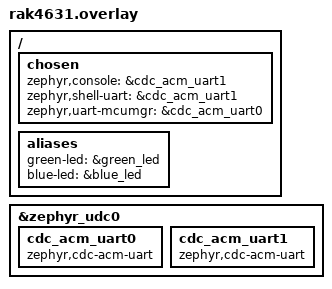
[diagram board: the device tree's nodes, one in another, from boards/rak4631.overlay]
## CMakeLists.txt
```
# Copyright (c) 2025 Kenneth Lu
#
# SPDX-License-Identifier: Apache-2.0

cmake_minimum_required(VERSION 3.20.0)

set(COMMON_PATH ${CMAKE_CURRENT_SOURCE_DIR}/../common)
include(${COMMON_PATH}/common.cmake)

find_package(Zephyr REQUIRED HINTS $ENV{ZEPHYR_BASE})
project(qthinger LANGUAGES C VERSION 1.0.0)

# determine git tag and commit hash for automatic firmware versioning
find_package(Git)
if(GIT_FOUND)
    execute_process(
        COMMAND ${GIT_EXECUTABLE} describe --long --dirty --tags
        OUTPUT_VARIABLE FIRMWARE_VERSION_ID
        OUTPUT_STRIP_TRAILING_WHITESPACE)
else()
    set(FIRMWARE_VERSION_ID "unknown")
endif()

add_definitions(-DFIRMWARE_VERSION_ID="${FIRMWARE_VERSION_ID}")

target_include_directories(app PRIVATE ${CMAKE_BINARY_DIR}/app/include src)
target_sources_ifdef(CONFIG_BOARD_RAK4631_NRF52840 app PRIVATE boards/board.c)
target_sources(app PRIVATE
      src/main.c
      src/data_objects.c
      src/ts_sensor.c
)
```

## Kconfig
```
# Copyright (c) 2021 Nordic Semiconductor ASA
#
# SPDX-License-Identifier: Apache-2.0

source "Kconfig.zephyr"

choice WISBLOCK_LORAWAN_REGION
	prompt "WisBlock LoRaWAN Region"
	default WISBLOCK_REGION_AS923
	help
	  Select the LoRaWAN region to use. This wrapper ensures only one
	  region is active at a time.

config WISBLOCK_REGION_AS923
	bool "Asia 923MHz (AS923)"
	select LORAMAC_REGION_AS923

config WISBLOCK_REGION_AU915
	bool "Australia 915MHz (AU915)"
	select LORAMAC_REGION_AU915

config WISBLOCK_REGION_CN470
	bool "China 470MHz (CN470)"
	select LORAMAC_REGION_CN470

config WISBLOCK_REGION_CN779
	bool "China 779MHz (CN779)"
	select LORAMAC_REGION_CN779

config WISBLOCK_REGION_EU433
	bool "Europe 433MHz (EU433)"
	select LORAMAC_REGION_EU433

config WISBLOCK_REGION_EU868
	bool "Europe 868MHz (EU868)"
	select LORAMAC_REGION_EU868

config WISBLOCK_REGION_KR920
	bool "Korea 920MHz (KR920)"
	select LORAMAC_REGION_KR920

config WISBLOCK_REGION_IN865
	bool "India 865MHz (IN865)"
	select LORAMAC_REGION_IN865

config WISBLOCK_REGION_US915
	bool "US 915MHz (US915)"
	select LORAMAC_REGION_US915

config WISBLOCK_REGION_RU864
	bool "Russia 864MHz (RU864)"
	select LORAMAC_REGION_RU864

endchoice
```

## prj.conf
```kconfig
CONFIG_LOG=y
CONFIG_MAIN_STACK_SIZE=2048
CONFIG_SYSTEM_WORKQUEUE_STACK_SIZE=2048

CONFIG_SHELL=y
CONFIG_NVS=y
CONFIG_ARM_MPU=n
CONFIG_FLASH=y
CONFIG_FLASH_PAGE_LAYOUT=y
CONFIG_FLASH_MAP=y
CONFIG_REBOOT=y

# ThingSet
CONFIG_THINGSET=y
CONFIG_THINGSET_SDK=y
CONFIG_THINGSET_NODE_NAME="RAKTS"
CONFIG_THINGSET_SHELL=y
CONFIG_THINGSET_SHELL_REPORTING=n
CONFIG_THINGSET_STORAGE=y
CONFIG_SHELL_WILDCARD=n
CONFIG_MPU_ALLOW_FLASH_WRITE=y
CONFIG_THINGSET_AUTH=y
CONFIG_THINGSET_AUTH_TOKEN_EXPERT="expert"
CONFIG_THINGSET_AUTH_TOKEN_MANUFACTURER="manufacturer"

CONFIG_BT=y
CONFIG_BT_PERIPHERAL=y
CONFIG_BT_DEVICE_NAME="RakThingSet"
CONFIG_BT_DEVICE_NAME_DYNAMIC=y
CONFIG_BT_GATT_CLIENT=y
CONFIG_BT_BUF_ACL_RX_SIZE=251
CONFIG_BT_BUF_ACL_TX_SIZE=251
CONFIG_BT_L2CAP_TX_MTU=251
CONFIG_BT_ID_MAX=2

CONFIG_THINGSET_BLE=y

# MCUBOOT
CONFIG_BOOTLOADER_MCUBOOT=y
CONFIG_MCUBOOT_SIGNATURE_KEY_FILE="bootloader/mcuboot/root-rsa-2048.pem"
CONFIG_MCUBOOT_GENERATE_CONFIRMED_IMAGE=y

# ZBUS
CONFIG_ZBUS=y

# Disable shell commands that are not needed
CONFIG_CLOCK_CONTROL_NRF_SHELL=n
CONFIG_DEVICE_SHELL=n
CONFIG_DEVMEM_SHELL=n
CONFIG_FLASH_SHELL=n

CONFIG_UART_LINE_CTRL=y
CONFIG_SHELL_BACKEND_SERIAL_CHECK_DTR=y

# Disable J-Link RTT libraries
CONFIG_USE_SEGGER_RTT=n

CONFIG_PICOLIBC=y
CONFIG_PICOLIBC_IO_FLOAT=y
```

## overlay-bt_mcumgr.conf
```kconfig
CONFIG_SAFEUPDATE=y

# Mcumgr
CONFIG_MCUMGR=y
CONFIG_MCUMGR_GRP_IMG=y
CONFIG_MCUMGR_GRP_OS=y
CONFIG_MCUMGR_GRP_SHELL=y
CONFIG_MCUMGR_TRANSPORT_UART=y
CONFIG_ZCBOR=y
CONFIG_BASE64=y
CONFIG_IMG_MANAGER=y
CONFIG_SHELL_BACKEND_DUMMY=y
CONFIG_STREAM_FLASH=y

#BT Mcumgr
CONFIG_BT_PERIPHERAL=y
CONFIG_BT_DEVICE_NAME_DYNAMIC=y
CONFIG_BT_CTLR_LE_PING=n
# Allow for large Bluetooth data packets.
CONFIG_BT_L2CAP_TX_MTU=498
CONFIG_BT_BUF_ACL_RX_SIZE=502
CONFIG_BT_BUF_ACL_TX_SIZE=502
CONFIG_BT_CTLR_DATA_LENGTH_MAX=251

# Enable the Bluetooth mcumgr transport (unauthenticated).
CONFIG_MCUMGR_TRANSPORT_BT=y
CONFIG_MCUMGR_TRANSPORT_BT_CONN_PARAM_CONTROL=y

CONFIG_MCUMGR_TRANSPORT_BT_REASSEMBLY=y
CONFIG_MCUMGR_TRANSPORT_NETBUF_SIZE=2475
CONFIG_MCUMGR_GRP_OS_MCUMGR_PARAMS=y
CONFIG_MCUMGR_TRANSPORT_WORKQUEUE_STACK_SIZE=4608
```

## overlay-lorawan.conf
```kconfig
CONFIG_LORA=y
CONFIG_LORA_SHELL=y
CONFIG_LORAWAN=y

CONFIG_THINGSET_LORAWAN=y
CONFIG_THINGSET_LORAWAN_ABP=y

CONFIG_ENTROPY_GENERATOR=y
CONFIG_ENTROPY_DEVICE_RANDOM_GENERATOR=y
```

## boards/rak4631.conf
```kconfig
CONFIG_SPI=y
CONFIG_GPIO=y

CONFIG_LORA=y
CONFIG_LORA_SX126X=y

# USB CDC ACM UART
CONFIG_USB_DEVICE_STACK=y
CONFIG_USB_DEVICE_VID=0x2FE9
CONFIG_USB_DEVICE_PRODUCT="QThinger"
CONFIG_USB_CDC_ACM_LOG_LEVEL_OFF=y
CONFIG_USB_COMPOSITE_DEVICE=y
CONFIG_USB_CDC_ACM_RINGBUF_SIZE=512
```

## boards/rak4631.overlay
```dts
/*
 * Copyright (c) 2025 Kenneth Lu
 *
 * SPDX-License-Identifier: Apache-2.0
 */

/ {
	chosen {
		zephyr,console = &cdc_acm_uart1;
		zephyr,shell-uart = &cdc_acm_uart1;
		zephyr,uart-mcumgr = &cdc_acm_uart0;
	};

	aliases {
		green-led = &green_led;
		blue-led = &blue_led;
	};
};

&zephyr_udc0 {
	cdc_acm_uart0: cdc_acm_uart0 {
		compatible = "zephyr,cdc-acm-uart";
	};

	cdc_acm_uart1: cdc_acm_uart1 {
		compatible = "zephyr,cdc-acm-uart";
	};
};
```

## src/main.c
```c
/*
 * Copyright (c) 2025 Kenneth Lu
 *
 * SPDX-License-Identifier: Apache-2.0
 */

#include <stdint.h>
#include <zephyr/kernel.h>
#include <zephyr/usb/usb_device.h>
#include <zephyr/drivers/uart.h>
#include <safeupdate/mcumgr_img.h>

#define LOG_LEVEL CONFIG_LOG_DEFAULT_LEVEL
#include <zephyr/logging/log.h>
LOG_MODULE_REGISTER(rakthingset);

int main(void)
{
	const struct device *const dev = DEVICE_DT_GET(DT_CHOSEN(zephyr_console));
	uint32_t dtr = 0;
	int rc;

	LOG_INF("Firmware: %s", FIRMWARE_VERSION_ID);
	LOG_INF("Build Time: " __DATE__ " " __TIME__);

	if (IS_ENABLED(CONFIG_USB_DEVICE_STACK)) {
		rc = usb_enable(NULL);
		if (rc) {
			LOG_ERR("Failed to enable USB");
		}
	}

	if (IS_ENABLED(CONFIG_SAFEUPDATE)) {
		LOG_INF("Init safeupdate mcumgr");
		safeudate_mcumgr_init();
	}

	/* Poll if the DTR flag was set */
	while (!dtr) {
		uart_line_ctrl_get(dev, UART_LINE_CTRL_DTR, &dtr);
		/* Give CPU resources to low priority threads. */
		k_sleep(K_MSEC(100));
	}

	return 0;
}
```

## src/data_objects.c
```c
/*
 * Copyright (c) 2025 Kenneth Lu
 *
 * SPDX-License-Identifier: Apache-2.0
 */

#include "data_objects.h"
#include <zephyr/kernel.h>
#include <zephyr/drivers/hwinfo.h>
#include <zephyr/sys/crc.h>
#include <zephyr/sys/reboot.h>
#include <thingset/sdk.h>
#include <thingset/storage.h>
#include <stdio.h>
#include <math.h>

#define LOG_LEVEL CONFIG_LOG_DEFAULT_LEVEL
#include <zephyr/logging/log.h>
LOG_MODULE_REGISTER(data_objs);

static char manufacturer[] = "RakThingSet";
static char firmware_version[] = FIRMWARE_VERSION_ID;
static float room_temp;
static float humidity;
static float target_temp = 22.0F;
static float OFFSET = 25.0f;
static float SCALING_FACTOR = 2.0f;
static bool heater_on;

/**
 * ThingSet data objects (see https://github.com/ThingSet)
 */

/* DEVICE INFORMATION */

THINGSET_ADD_GROUP(TS_ID_ROOT, APP_ID_DEVICE, "Device", THINGSET_NO_CALLBACK);

THINGSET_ADD_ITEM_STRING(APP_ID_DEVICE, APP_ID_DEVICE_MANUFACTURER, "cManufacturer", manufacturer,
			 sizeof(manufacturer), THINGSET_ANY_R, 0);

THINGSET_ADD_ITEM_STRING(APP_ID_DEVICE, APP_ID_DEVICE_FW_VER, "cFirmwareVersion", firmware_version,
			 sizeof(firmware_version), THINGSET_ANY_R, 0);

THINGSET_ADD_FN_VOID(APP_ID_DEVICE, APP_ID_DEVICE_RESET, "xReset", &reset_device, THINGSET_ANY_RW);

/* SENSOR DATA */
THINGSET_ADD_GROUP(TS_ID_ROOT, APP_ID_SENSOR, "Sensor", THINGSET_NO_CALLBACK);

THINGSET_ADD_ITEM_FLOAT(APP_ID_SENSOR, APP_ID_SENSOR_TEMP, "rRoomTemp_degC", &room_temp, 1,
			THINGSET_ANY_R, TS_SUBSET_SUMMARY);

THINGSET_ADD_ITEM_FLOAT(APP_ID_SENSOR, APP_ID_SENSOR_HUMIDITY, "rHumidity_pct", &humidity, 1,
			THINGSET_ANY_R, TS_SUBSET_SUMMARY);

/* CONTROL */
THINGSET_ADD_GROUP(TS_ID_ROOT, APP_ID_CONTROL, "Control", THINGSET_NO_CALLBACK);

THINGSET_ADD_ITEM_BOOL(APP_ID_CONTROL, APP_ID_CONTROL_HEATER_ON, "rHeaterOn", &heater_on,
		       THINGSET_ANY_R, TS_SUBSET_LIVE);

THINGSET_ADD_ITEM_FLOAT(APP_ID_CONTROL, APP_ID_CONTROL_TARGET_TEMP, "sTargetTemp_degC",
			&target_temp, 1, THINGSET_ANY_RW, TS_SUBSET_NVM);

static uint8_t data_objects_encode_sensor_val(float sensor_val)
{
	float calculated_value = (sensor_val + OFFSET) * SCALING_FACTOR;

	return roundf(calculated_value);
}

void reset_device(void)
{
	sys_reboot(SYS_REBOOT_COLD);
}

void data_objects_sensor_data(struct sensor_zmsg *s_zmsg)
{
	switch (s_zmsg->type) {
	case SENSOR_CHAN_AMBIENT_TEMP:
		room_temp = sensor_value_to_double(&s_zmsg->data);
		break;
	case SENSOR_CHAN_HUMIDITY:
		humidity = sensor_value_to_double(&s_zmsg->data);
		break;
	default:
		break;
	}
}

uint8_t data_objects_get_sensor_value(uint8_t sensor_type)
{
	uint8_t val = 0;

	switch (sensor_type) {
	case SENSOR_CHAN_AMBIENT_TEMP:
		val = data_objects_encode_sensor_val(room_temp);
		break;
	case SENSOR_CHAN_HUMIDITY:
		val = data_objects_encode_sensor_val(humidity);
		break;
	default:
		break;
	}

	return val;
}
```

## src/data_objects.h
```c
/*
 * Copyright (c) 2025 Kenneth Lu
 *
 * SPDX-License-Identifier: Apache-2.0
 */

#ifndef DATA_OBJECTS_H_
#define DATA_OBJECTS_H_

/**
 * @file
 * @brief Handling of ThingSet data nodes
 */

#include <thingset.h>
#include <stdbool.h>
#include <stdint.h>
#include <string.h>
#include <zbus_ext/zbus_ext.h>

/*
 * Categories / first layer node IDs
 */

/* Device information (e.g. manufacturer, etc.) */
#define APP_ID_DEVICE		   0x04
#define APP_ID_DEVICE_MANUFACTURER 0x40
#define APP_ID_DEVICE_TYPE	   0x41
#define APP_ID_DEVICE_HW_VER	   0x42
#define APP_ID_DEVICE_FW_VER	   0x43
#define APP_ID_DEVICE_SHUTDOWN	   0x4A
#define APP_ID_DEVICE_RESET	   0x4B

/* Sensor data */
#define APP_ID_SENSOR	       0x05
#define APP_ID_SENSOR_TEMP     0x50
#define APP_ID_SENSOR_HUMIDITY 0x51

/* Control data */
#define APP_ID_CONTROL		   0x06
#define APP_ID_CONTROL_HEATER_ON   0x60
#define APP_ID_CONTROL_TARGET_TEMP 0x61

/* Openhaystack data */
#define APP_ID_OHS 0x07

/**
 * Callback to reset device (obviously...)
 */
void reset_device(void);

/**
 * Callback function to be called when conf values were changed
 */
void data_objects_update_conf(enum thingset_callback_reason reason);

/**
 * function to update sensor data from zbus
 */
void data_objects_sensor_data(struct sensor_zmsg *s_zmsg);

/**
 * function to get sensor value by type
 */
uint8_t data_objects_get_sensor_value(uint8_t sensor_type);

#endif /* DATA_OBJECTS_H_ */
```

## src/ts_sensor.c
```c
/*
 * Copyright (c) 2025 Kenneth Lu
 *
 * SPDX-License-Identifier: Apache-2.0
 */

#include <stdlib.h>
#include <thingset.h>
#include <thingset/sdk.h>
#include <zephyr/kernel.h>
#include "data_objects.h"

#define LOG_LEVEL CONFIG_LOG_DEFAULT_LEVEL
#include <zephyr/logging/log.h>
LOG_MODULE_REGISTER(ts_sensor);

#define PRIORITY 7

ZBUS_CHAN_DEFINE(sensor_data_chan,   /* Name */
		 struct sensor_zmsg, /* Message type */

		 NULL,			       /* Validator */
		 NULL,			       /* User data */
		 ZBUS_OBSERVERS(thingset_sub), /* observers */
		 ZBUS_MSG_INIT(0)	       /* Initial value {0} */
);
ZBUS_SUBSCRIBER_DEFINE(thingset_sub, 4);
ZBUS_CHAN_DECLARE(sensor_data_chan);

static void thingset_sensor_start(void)
{
	int ret;
	const struct zbus_channel *chan;
	struct sensor_zmsg s_zmsg;

	while (!zbus_sub_wait(&thingset_sub, &chan, K_FOREVER)) {
		if (&sensor_data_chan == chan) {
			ret = zbus_chan_read(&sensor_data_chan, &s_zmsg, K_MSEC(500));

			if (ret < 0) {
				LOG_ERR("zbus read data failed");
				continue;
			}

			data_objects_sensor_data(&s_zmsg);
		}
	}
}

K_THREAD_DEFINE(thingset_sensor, 1024, thingset_sensor_start, NULL, NULL, NULL, PRIORITY, 0, 0);
```
